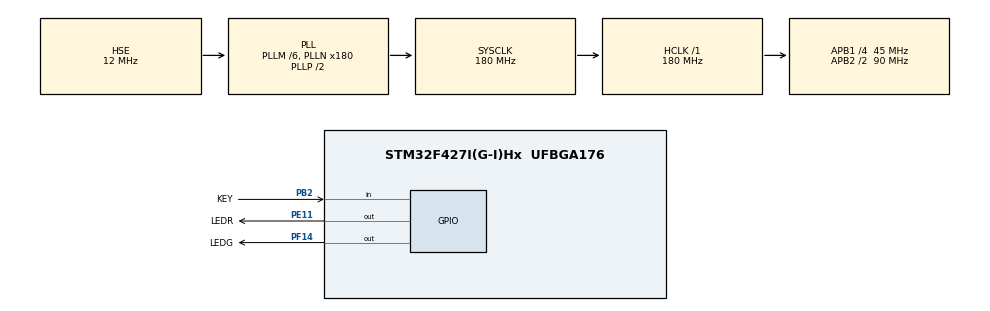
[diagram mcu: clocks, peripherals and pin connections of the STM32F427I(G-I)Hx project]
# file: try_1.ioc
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Mcu.Family=STM32F4
Mcu.Name=STM32F427I(G-I)Hx
Mcu.Package=UFBGA176
NVIC.PriorityGroup=NVIC_PRIORITYGROUP_4
PA13.Mode=Serial_Wire
PA13.Signal=SYS_JTMS-SWDIO
PA14.Mode=Serial_Wire
PA14.Signal=SYS_JTCK-SWCLK
PB2/BOOT1.GPIO_Label=KEY
PB2/BOOT1.GPIO_PuPd=GPIO_PULLDOWN
PB2/BOOT1.Signal=GPIO_Input
PE11.GPIO_Label=LEDR
PE11.Signal=GPIO_Output
PF14.GPIO_Label=LEDG
PF14.Signal=GPIO_Output
PH0/OSC_IN.Mode=HSE-External-Oscillator
PH0/OSC_IN.Signal=RCC_OSC_IN
PH1/OSC_OUT.Mode=HSE-External-Oscillator
PH1/OSC_OUT.Signal=RCC_OSC_OUT
ProjectManager.HeapSize=0x200
ProjectManager.StackSize=0x400
ProjectManager.TargetToolchain=MDK-ARM V5.32
RCC.48MHZClocksFreq_Value=90000000
RCC.AHBFreq_Value=180000000
RCC.APB1CLKDivider=RCC_HCLK_DIV4
RCC.APB1Freq_Value=45000000
RCC.APB1TimFreq_Value=90000000
RCC.APB2CLKDivider=RCC_HCLK_DIV2
RCC.APB2Freq_Value=90000000
RCC.APB2TimFreq_Value=180000000
RCC.CortexFreq_Value=180000000
RCC.HCLKFreq_Value=180000000
RCC.HSE_VALUE=12000000
RCC.HSI_VALUE=16000000
RCC.LSE_VALUE=32768
RCC.PLLM=6
RCC.PLLN=180
RCC.PLLSourceVirtual=RCC_PLLSOURCE_HSE
RCC.SYSCLKFreq_VALUE=180000000
RCC.SYSCLKSource=RCC_SYSCLKSOURCE_PLLCLK
RCC.VCOOutputFreq_Value=360000000
board=custom

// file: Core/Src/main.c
/* USER CODE BEGIN Header */
/**
  ******************************************************************************
  * @file           : main.c
  * @brief          : Main program body
  ******************************************************************************
  * @attention
  *
  * Copyright (c) 2025 STMicroelectronics.
  * All rights reserved.
  *
  * This software is licensed under terms that can be found in the LICENSE file
  * in the root directory of this software component.
  * If no LICENSE file comes with this software, it is provided AS-IS.
  *
  ******************************************************************************
  */
/* USER CODE END Header */
#include "main.h"
#include "gpio.h"

/* USER CODE BEGIN PV */
uint32_t ticks;
uint32_t flag = 0;
uint32_t clock = 0;
uint8_t key_lock = 1;
uint32_t ticks_1=0,ticks_2=0;
uint32_t key_pressed = 0;
uint32_t last_key_time = 0;

/* USER CODE END PV */

void SystemClock_Config(void);

int main(void)
{

  /* MCU Configuration--------------------------------------------------------*/

  /* Reset of all peripherals, Initializes the Flash interface and the Systick. */
  HAL_Init();

  /* Configure the system clock */
  SystemClock_Config();

  /* Initialize all configured peripherals */
  MX_GPIO_Init();

  /* Infinite loop */
  /* USER CODE BEGIN WHILE */

  while (1)
  {

    if (HAL_GPIO_ReadPin(KEY_GPIO_Port, KEY_Pin))
    {
      HAL_Delay(20);
      while (HAL_GPIO_ReadPin(KEY_GPIO_Port, KEY_Pin)) {}
      HAL_Delay(1);
      flag = !flag;
    }

    /*
    if (HAL_GPIO_ReadPin(KEY_GPIO_Port, KEY_Pin))
    {
      ticks_1 = HAL_GetTick();
    }
    while (HAL_GPIO_ReadPin(KEY_GPIO_Port, KEY_Pin)) {}
    ticks_2 = HAL_GetTick();
    if (ticks_2-ticks_1 > 100)
    {
      flag = !flag;
    }
    */

    /*
    uint8_t current_key_state = HAL_GPIO_ReadPin(KEY_GPIO_Port, KEY_Pin);

    if (current_key_state && !key_pressed)
    {
      if ((HAL_GetTick() - last_key_time) > 50) // 50ms消抖
      {
        flag = !flag;
        key_pressed = 1;
        last_key_time = HAL_GetTick();
      }
    }
    else if (!current_key_state)
    {
      key_pressed = 0;
    }
    */

    if (flag)
    {
      HAL_GPIO_WritePin(LEDG_GPIO_Port, LEDG_Pin, GPIO_PIN_SET);
      HAL_Delay(100);
      HAL_GPIO_WritePin(LEDR_GPIO_Port, LEDR_Pin, GPIO_PIN_SET);
      HAL_Delay(100);
      ticks = HAL_GetTick();
      HAL_GPIO_WritePin(LEDR_GPIO_Port, LEDR_Pin, GPIO_PIN_RESET);
      HAL_Delay(100);
      HAL_GPIO_WritePin(LEDR_GPIO_Port, LEDR_Pin, GPIO_PIN_SET);
      HAL_Delay(100);
    } else
    {
      HAL_GPIO_WritePin(LEDG_GPIO_Port, LEDG_Pin, GPIO_PIN_SET);
      HAL_Delay(100);
      HAL_GPIO_WritePin(LEDR_GPIO_Port, LEDR_Pin, GPIO_PIN_SET);
      HAL_Delay(100);
      ticks = HAL_GetTick();
      HAL_GPIO_WritePin(LEDG_GPIO_Port, LEDG_Pin, GPIO_PIN_RESET);
      HAL_Delay(100);
      HAL_GPIO_WritePin(LEDG_GPIO_Port, LEDG_Pin, GPIO_PIN_SET);
      HAL_Delay(100);
    }

//     /*-------- 1. 按键检测（阻塞等待松手） --------*/
//     uint8_t key = HAL_GPIO_ReadPin(KEY_GPIO_Port, KEY_Pin);
//     if (key_lock && key == 0)      // 假设按键按下为低电平
//     {
//       HAL_Delay(50);             // 简单消抖
//       if (HAL_GPIO_ReadPin(KEY_GPIO_Port, KEY_Pin) == 0)
//       {
//         flag = !flag;          // 翻转状态
//         key_lock = 0;          // 进入“等待松手”
//       }
//     }
//     if (key == 1) key_lock = 1;    // 已松手，允许下一次触发
//
//     /*-------- 2. 根据 flag 闪灯（阻塞 1 s） --------*/
//     if (flag)                      // 红灯阶段
//     {
//       HAL_GPIO_WritePin(LEDG_GPIO_Port, LEDG_Pin, GPIO_PIN_SET); // 确保绿灯灭
//       HAL_GPIO_TogglePin(LEDR_GPIO_Port, LEDR_Pin);
//       HAL_Delay(1000);
//     }
//     else                           // 绿灯阶段
//     {
//       HAL_GPIO_WritePin(LEDR_GPIO_Port, LEDR_Pin, GPIO_PIN_SET); // 确保红灯灭
//       HAL_GPIO_TogglePin(LEDG_GPIO_Port, LEDG_Pin);
//       HAL_Delay(1000);
//     }

    /* USER CODE END WHILE */

  }
}

void SystemClock_Config(void)
{
  RCC_OscInitTypeDef RCC_OscInitStruct = {0};
  RCC_ClkInitTypeDef RCC_ClkInitStruct = {0};

  /** Configure the main internal regulator output voltage
  */
  __HAL_RCC_PWR_CLK_ENABLE();
  __HAL_PWR_VOLTAGESCALING_CONFIG(PWR_REGULATOR_VOLTAGE_SCALE1);

  /** Initializes the RCC Oscillators according to the specified parameters
  * in the RCC_OscInitTypeDef structure.
  */
  RCC_OscInitStruct.OscillatorType = RCC_OSCILLATORTYPE_HSE;
  RCC_OscInitStruct.HSEState = RCC_HSE_ON;
  RCC_OscInitStruct.PLL.PLLState = RCC_PLL_ON;
  RCC_OscInitStruct.PLL.PLLSource = RCC_PLLSOURCE_HSE;
  RCC_OscInitStruct.PLL.PLLM = 6;
  RCC_OscInitStruct.PLL.PLLN = 180;
  RCC_OscInitStruct.PLL.PLLP = RCC_PLLP_DIV2;
  RCC_OscInitStruct.PLL.PLLQ = 4;
  if (HAL_RCC_OscConfig(&RCC_OscInitStruct) != HAL_OK)
  {
    Error_Handler();
  }

  /** Activate the Over-Drive mode
  */
  if (HAL_PWREx_EnableOverDrive() != HAL_OK)
  {
    Error_Handler();
  }

  /** Initializes the CPU, AHB and APB buses clocks
  */
  RCC_ClkInitStruct.ClockType = RCC_CLOCKTYPE_HCLK|RCC_CLOCKTYPE_SYSCLK
                              |RCC_CLOCKTYPE_PCLK1|RCC_CLOCKTYPE_PCLK2;
  RCC_ClkInitStruct.SYSCLKSource = RCC_SYSCLKSOURCE_PLLCLK;
  RCC_ClkInitStruct.AHBCLKDivider = RCC_SYSCLK_DIV1;
  RCC_ClkInitStruct.APB1CLKDivider = RCC_HCLK_DIV4;
  RCC_ClkInitStruct.APB2CLKDivider = RCC_HCLK_DIV2;

  if (HAL_RCC_ClockConfig(&RCC_ClkInitStruct, FLASH_LATENCY_5) != HAL_OK)
  {
    Error_Handler();
  }
}

void Error_Handler(void)
{
  __disable_irq();
  while (1)
  {
  }
}
